# RX64M_WDT_Pilot register map
File version: 1.0
RX64M_WDT_Pilot peripheral registers generated from iodefine.h (pilot).
Registers are 8-bit, read-write, reset 0xFF unless marked. A register's access mark holds for its fields unless they carry their own. Offsets are from the block's base; lines under a group give offsets from that group; [hi:lo] are bit positions; {n}, {i} and the like mark numbered series; 'fields as' and 'values as' point back to an identical list; <NAME> marks a mode.

## Memory map
0x00088020 WDT size 0x7

## WDT
Base 0x00088020
0x00 WDTRR
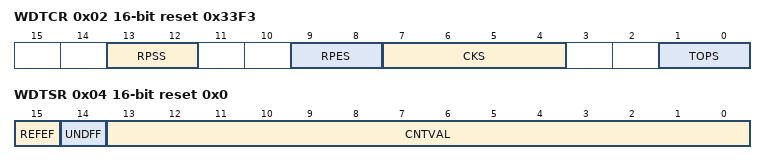
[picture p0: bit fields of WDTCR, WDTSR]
0x02 WDTCR 16-bit reset 0x33F3
  [13:12] RPSS, [9:8] RPES, [7:4] CKS, [1:0] TOPS
0x04 WDTSR 16-bit reset 0x0
  [15] REFEF, [14] UNDFF, [13:0] CNTVAL
0x06 WDTRCR reset 0x80
  [7] RSTIRQS
